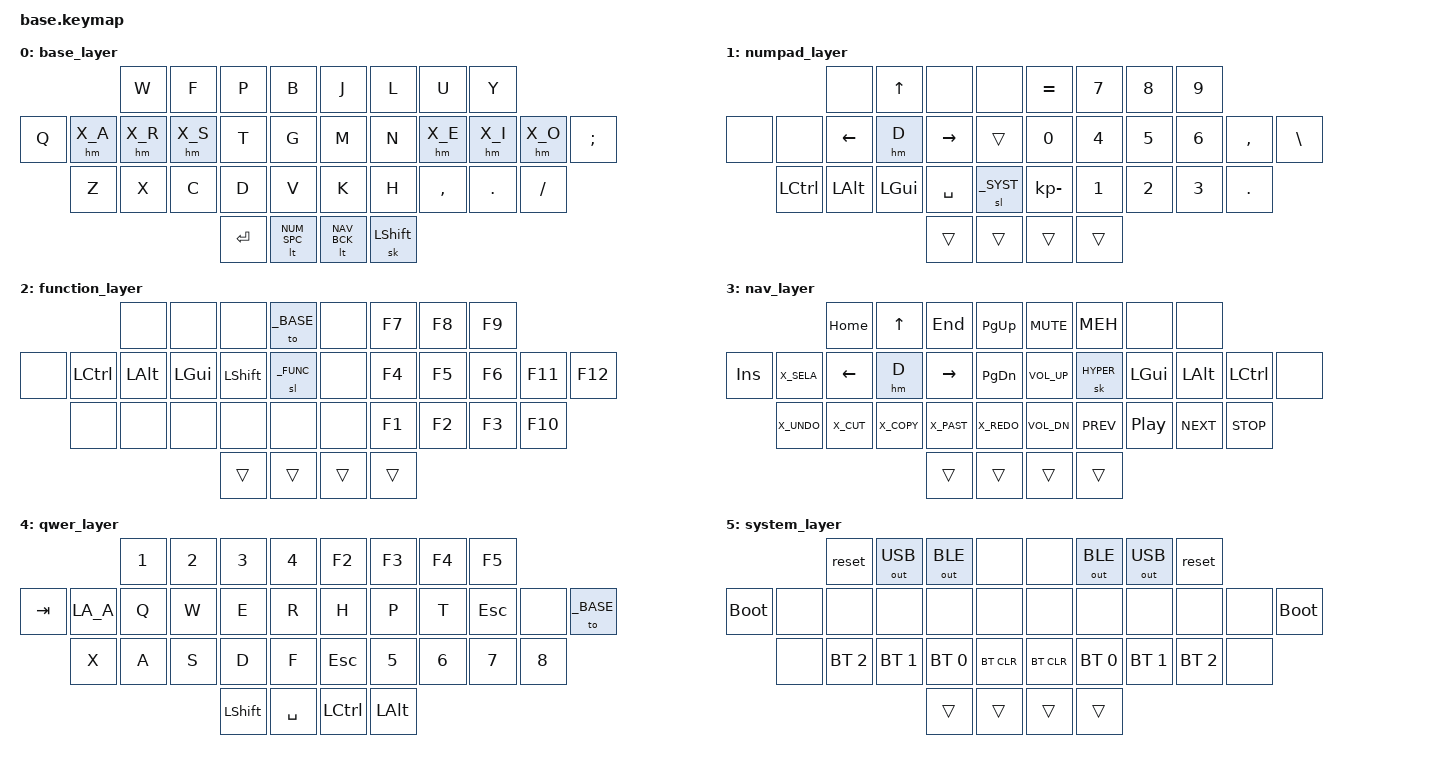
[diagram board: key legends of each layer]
#include <behaviors.dtsi>
#include <dt-bindings/zmk/keys.h>
#include <dt-bindings/zmk/bt.h>
#include <dt-bindings/zmk/outputs.h>
#include "deek.h"

&lt {
        tapping-term-ms = <150>;
        flavor = "tap-preferred";
        quick-tap-ms = <100>;
};

&sk {
        release-after-ms = <1000>;
        quick-release;
};

&sl {
    /delete-property/ quick-release;
};

/ {
    behaviors {
        hm: homerow_mods {
            compatible = "zmk,behavior-hold-tap";
            label = "HOMEROW_MODS";
            #binding-cells = <2>;
            tapping-term-ms = <250>;
            quick_tap_ms = <0>;
            flavor = "tap-preferred";
            bindings = <&kp>, <&kp>;
        };
        ss: sticky_shift {
            compatible = "zmk,behavior-hold-tap";
            label = "STICKY_SHIFT";
            #binding-cells = <2>;
            tapping-term-ms = <150>;
            quick_tap_ms = <0>;
            flavor = "tap-preferred";
            bindings = <&kp>, <&sk>;
        };
    };

    combos {
        #include "combos.def"
    };

    keymap {
        compatible = "zmk,keymap";

        base_layer {
            bindings = <
                              &kp W      &kp F       &kp P      &kp B            &kp J       &kp L      &kp U       &kp Y 
            &kp Q &hm X_A     &hm X_R    &hm X_S     &kp T      &kp G            &kp M       &kp N      &hm X_E     &hm X_I     &hm X_O  &kp SEMI
                  &kp Z       &kp X      &kp C       &kp D      &kp V            &kp K       &kp H      &kp COMMA   &kp DOT     &kp FSLH
                                                     &kp ENTER  &lt NUM_SPC      &lt NAV_BCK &sk LSHIFT
            >;
        };

        numpad_layer {
            bindings = <
                            &none    &kp UP   &none     &none          &kp EQUAL    &kp N7    &kp N8   &kp N9  
            &none &none     &kp LEFT &hm C_D  &kp RIGHT &trans         &kp N0       &kp N4    &kp N5   &kp N6   &kp COMMA &kp BSLH 
                  &kp LCTRL &kp LALT &kp LGUI &kp SPACE &sl _SYST      &kp KP_MINUS &kp N1    &kp N2   &kp N3   &kp DOT  
                                              &trans    &trans         &trans       &trans
            >;
        };

        function_layer {
            bindings = <
                              &none        &none        &none      &to _BASE            &none   &kp F7  &kp F8 &kp F9
            &none    &kp LCTRL &kp LALT     &kp LGUI    &kp LSHFT  &sl _FUNC            &none   &kp F4  &kp F5 &kp F6 &kp F11      &kp F12     
                     &none    &none        &none        &none      &none                &none   &kp F1  &kp F2 &kp F3 &kp F10  
                                                        &trans     &trans               &trans  &trans 
            >;
        };

        nav_layer {
            bindings = <
                                   &kp HOME     &kp UP       &kp END      &kp PG_UP        &kp C_MUTE   &kp MEH      &none        &none
             &kp INS  &kp X_SELA   &kp LEFT     &hm C_D      &kp RIGHT    &kp PG_DN        &kp C_VOL_UP &sk HYPER    &kp LGUI     &kp LALT   &kp LCTRL &none
                      &kp X_UNDO   &kp X_CUT    &kp X_COPY   &kp X_PAST   &kp X_REDO       &kp C_VOL_DN &kp C_PREV   &kp C_PP     &kp C_NEXT &kp C_STOP
                                                             &trans       &trans           &trans       &trans
            >;
        };

        qwer_layer {
            bindings = <
                                &kp N1  &kp N2  &kp N3  &kp N4        &kp F2     &kp F3  &kp F4  &kp F5
             &kp TAB  &kp LA_A  &kp Q   &kp W   &kp E   &kp R         &kp H      &kp P   &kp T   &kp ESC  &none  &to _BASE
                      &kp X     &kp A   &kp S   &kp D   &kp F         &kp ESC    &kp N5  &kp N6  &kp N7   &kp N8 
                                    &kp LSHIFT    &kp SPACE           &kp LCTRL  &kp LALT
            >;
        };

        system_layer {
            bindings = <
                                      &reset       &out OUT_USB &out OUT_BLE &none            &none        &out OUT_BLE &out OUT_USB &reset
             &bootloader &none        &none        &none        &none        &none            &none        &none        &none        &none        &none     &bootloader
                         &none        &bt BT_SEL 2 &bt BT_SEL 1 &bt BT_SEL 0 &bt BT_CLR       &bt BT_CLR   &bt BT_SEL 0 &bt BT_SEL 1 &bt BT_SEL 2 &none     
                                                                &trans       &trans           &trans       &trans
            >;
        };
    };
};
